AUTOSAR XML (schema 00051)
package /Components
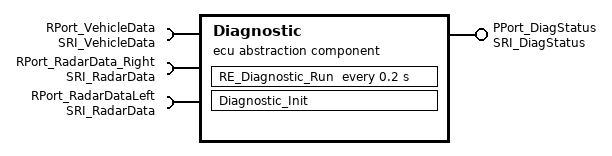
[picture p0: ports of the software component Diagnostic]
  ecu abstraction sw component type Diagnostic
    require port RPort_VehicleData: required-interface=SRI_VehicleData
      required-com-specs:
        data-element=Steering_Status, init-value=SIGNAL_OK
        data-element=Gear_Status, init-value=SIGNAL_OK
        data-element=TurnSignal_Status, init-value=SIGNAL_OK
        data-element=Speed_Status, init-value=SIGNAL_OK
        data-element=Steering_Angle, init-value=0
        data-element=Gear, init-value=GEAR_PARK
        data-element=TurnSignal, init-value=TURN_OFF
        data-element=Vehicle_Speed, init-value=0
    require port RPort_RadarData_Right: required-com-specs=[{data-element=Status, init-value=RADAR_OK}, {data-element=Distance, init-value=0}], required-interface=SRI_RadarData
    require port RPort_RadarDataLeft: required-com-specs=[{data-element=Status, init-value=RADAR_OK}, {data-element=Distance, init-value=0}], required-interface=SRI_RadarData
    provide port PPort_DiagStatus: provided-interface=SRI_DiagStatus
      provided-com-specs:
        data-element=Steering_Event, init-value=DIAG_EVT_PASSED
        data-element=Radar_Left_Event, init-value=DIAG_EVT_PASSED
        data-element=Radar_Right_Event, init-value=DIAG_EVT_PASSED
        data-element=Speed_Event, init-value=DIAG_EVT_PASSED
        data-element=TurnSignal_Event, init-value=DIAG_EVT_PASSED
        data-element=Gear_Event, init-value=DIAG_EVT_PASSED
    behavior Diagnostic_IB: data-type-mapping=bsdDataTypeMappingsSet, handle-termination-and-restart=NO-SUPPORT
      timing event TE_Diagnostic_20ms: start-on-event=RE_Diagnostic_Run, period=0.2
      runnable Diagnostic_Init
      runnable RE_Diagnostic_Run
        data-read-access:
          6 x access:
            IN_RPort_RadarDataLeft_Status: accessed-variable=RPort_RadarDataLeft.Status
            IN_RPort_VehicleData_Speed_Status: accessed-variable=RPort_VehicleData.Speed_Status
            IN_RPort_RadarData_Right_Status: accessed-variable=RPort_RadarData_Right.Status
            IN_RPort_VehicleData_Steering_Status: accessed-variable=RPort_VehicleData.Steering_Status
            IN_RPort_VehicleData_Gear_Status: accessed-variable=RPort_VehicleData.Gear_Status
            IN_RPort_VehicleData_TurnSignal_Status: accessed-variable=RPort_VehicleData.TurnSignal_Status
        data-write-access:
          6 x access:
            OUT_PPort_DiagStatus_Steering_Event: accessed-variable=PPort_DiagStatus.Steering_Event
            OUT_PPort_DiagStatus_Radar_Left_Event: accessed-variable=PPort_DiagStatus.Radar_Left_Event
            OUT_PPort_DiagStatus_Radar_Right_Event: accessed-variable=PPort_DiagStatus.Radar_Right_Event
            OUT_PPort_DiagStatus_Speed_Event: accessed-variable=PPort_DiagStatus.Speed_Event
            OUT_PPort_DiagStatus_TurnSignal_Event: accessed-variable=PPort_DiagStatus.TurnSignal_Event
            OUT_PPort_DiagStatus_Gear_Event: accessed-variable=PPort_DiagStatus.Gear_Event
